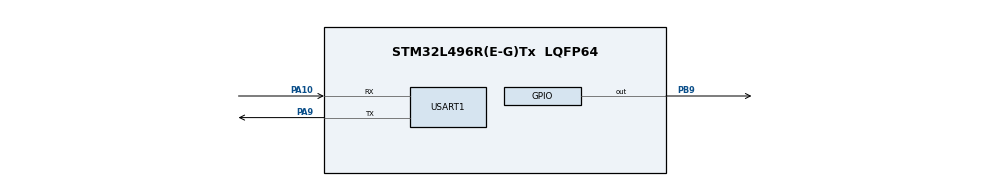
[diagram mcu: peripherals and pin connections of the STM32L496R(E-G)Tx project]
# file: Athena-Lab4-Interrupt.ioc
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FREERTOS.Tasks01=defaultTask,24,128,StartDefaultTask,Default,NULL,Dynamic,NULL,NULL
Mcu.Family=STM32L4
Mcu.Name=STM32L496R(E-G)Tx
Mcu.Package=LQFP64
NVIC.PriorityGroup=NVIC_PRIORITYGROUP_4
NVIC.TIM1_UP_TIM16_IRQn=true\:15\:0\:false\:false\:true\:false\:false\:true\:true
NVIC.TimeBase=TIM1_UP_TIM16_IRQn
NVIC.TimeBaseIP=TIM1
NVIC.USART1_IRQn=true\:5\:0\:false\:false\:true\:true\:true\:true\:true
PA10.Mode=Asynchronous
PA10.Signal=USART1_RX
PA13\ (JTMS/SWDIO).Mode=Serial_Wire
PA13\ (JTMS/SWDIO).Signal=SYS_JTMS-SWDIO
PA14\ (JTCK/SWCLK).Mode=Serial_Wire
PA14\ (JTCK/SWCLK).Signal=SYS_JTCK-SWCLK
PA9.Mode=Asynchronous
PA9.Signal=USART1_TX
PB9.Signal=GPIO_Output
PH0-OSC_IN\ (PH0).Mode=HSE-External-Oscillator
PH0-OSC_IN\ (PH0).Signal=RCC_OSC_IN
PH1-OSC_OUT\ (PH1).Mode=HSE-External-Oscillator
PH1-OSC_OUT\ (PH1).Signal=RCC_OSC_OUT
ProjectManager.HeapSize=0x200
ProjectManager.StackSize=0x400
ProjectManager.TargetToolchain=STM32CubeIDE
RCC.ADCFreq_Value=32000000
RCC.AHBFreq_Value=80000000
RCC.APB1Freq_Value=80000000
RCC.APB1TimFreq_Value=80000000
RCC.APB2Freq_Value=80000000
RCC.APB2TimFreq_Value=80000000
RCC.CortexFreq_Value=80000000
RCC.HCLKFreq_Value=80000000
RCC.HSE_VALUE=8000000
RCC.HSI48_VALUE=48000000
RCC.HSI_VALUE=16000000
RCC.LSE_VALUE=32768
RCC.MSI_VALUE=4000000
RCC.PLLN=20
RCC.PLLSourceVirtual=RCC_PLLSOURCE_HSE
RCC.SYSCLKFreq_VALUE=80000000
RCC.SYSCLKSource=RCC_SYSCLKSOURCE_PLLCLK
RCC.USBFreq_Value=32000000
RCC.VCOOutputFreq_Value=160000000
USART1.VirtualMode-Asynchronous=VM_ASYNC
VP_FREERTOS_VS_CMSIS_V2.Mode=CMSIS_V2
VP_SYS_VS_tim1.Mode=TIM1
board=custom

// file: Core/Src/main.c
/* USER CODE BEGIN Header */
/**
  ******************************************************************************
  * @file           : main.c
  * @brief          : Main program body
  ******************************************************************************
  * @attention
  *
  * Copyright (c) 2025 STMicroelectronics.
  * All rights reserved.
  *
  * This software is licensed under terms that can be found in the LICENSE file
  * in the root directory of this software component.
  * If no LICENSE file comes with this software, it is provided AS-IS.
  *
  ******************************************************************************
  */
/* USER CODE END Header */
#include "main.h"
#include "cmsis_os.h"
#include "usart.h"
#include "gpio.h"

void SystemClock_Config(void);
void MX_FREERTOS_Init(void);

int main(void)
{

  /* MCU Configuration--------------------------------------------------------*/

  /* Reset of all peripherals, Initializes the Flash interface and the Systick. */
  HAL_Init();

  /* Configure the system clock */
  SystemClock_Config();

  /* Initialize all configured peripherals */
  MX_GPIO_Init();
  MX_USART1_UART_Init();

  /* Init scheduler */
  osKernelInitialize();  /* Call init function for freertos objects (in cmsis_os2.c) */
  MX_FREERTOS_Init();

  /* Start scheduler */
  osKernelStart();

  /* We should never get here as control is now taken by the scheduler */

  /* Infinite loop */
  while (1)
  {

  }
}

void SystemClock_Config(void)
{
  LL_FLASH_SetLatency(LL_FLASH_LATENCY_4);
  while(LL_FLASH_GetLatency()!= LL_FLASH_LATENCY_4)
  {
  }
  LL_PWR_SetRegulVoltageScaling(LL_PWR_REGU_VOLTAGE_SCALE1);
  while (LL_PWR_IsActiveFlag_VOS() != 0)
  {
  }
  LL_RCC_HSE_Enable();

   /* Wait till HSE is ready */
  while(LL_RCC_HSE_IsReady() != 1)
  {

  }
  LL_RCC_PLL_ConfigDomain_SYS(LL_RCC_PLLSOURCE_HSE, LL_RCC_PLLM_DIV_1, 20, LL_RCC_PLLR_DIV_2);
  LL_RCC_PLL_EnableDomain_SYS();
  LL_RCC_PLL_Enable();

   /* Wait till PLL is ready */
  while(LL_RCC_PLL_IsReady() != 1)
  {

  }
  LL_RCC_SetSysClkSource(LL_RCC_SYS_CLKSOURCE_PLL);

   /* Wait till System clock is ready */
  while(LL_RCC_GetSysClkSource() != LL_RCC_SYS_CLKSOURCE_STATUS_PLL)
  {

  }
  LL_RCC_SetAHBPrescaler(LL_RCC_SYSCLK_DIV_1);
  LL_RCC_SetAPB1Prescaler(LL_RCC_APB1_DIV_1);
  LL_RCC_SetAPB2Prescaler(LL_RCC_APB2_DIV_1);
  LL_SetSystemCoreClock(80000000);

   /* Update the time base */
  if (HAL_InitTick (TICK_INT_PRIORITY) != HAL_OK)
  {
    Error_Handler();
  }
}

void HAL_TIM_PeriodElapsedCallback(TIM_HandleTypeDef *htim)
{
  if (htim->Instance == TIM1)
  {
    HAL_IncTick();
  }
}

void Error_Handler(void)
{
  __disable_irq();
  while (1)
  {
  }
}

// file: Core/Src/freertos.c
/* USER CODE BEGIN Header */
/**
  ******************************************************************************
  * File Name          : freertos.c
  * Description        : Code for freertos applications
  ******************************************************************************
  * @attention
  *
  * Copyright (c) 2025 STMicroelectronics.
  * All rights reserved.
  *
  * This software is licensed under terms that can be found in the LICENSE file
  * in the root directory of this software component.
  * If no LICENSE file comes with this software, it is provided AS-IS.
  *
  ******************************************************************************
  */
/* USER CODE END Header */

#include "FreeRTOS.h"
#include "task.h"
#include "main.h"
#include "cmsis_os.h"

/* USER CODE BEGIN Includes */
#include <string.h>
/* USER CODE END Includes */

/* USER CODE BEGIN Variables */
//======== Add Code in this area begin ========
// Import header file, define task handle, define semaphore, declare task function

//======== Add Code in this area end ========

uint8_t work_flag = 1;
uint32_t led_blink_timedelay = 1000;
usart1_rxbuffer rx_buffer;
/* USER CODE END Variables */
/* Definitions for defaultTask */
osThreadId_t defaultTaskHandle;
const osThreadAttr_t defaultTask_attributes = {
  .name = "defaultTask",
  .stack_size = 128 * 4,
  .priority = (osPriority_t) osPriorityNormal,
};

void StartDefaultTask(void *argument);

void MX_FREERTOS_Init(void); /* (MISRA C 2004 rule 8.1) */

void MX_FREERTOS_Init(void) {

  /* USER CODE BEGIN RTOS_SEMAPHORES */
  /* add semaphores, ... */

  //======== Add Code in this area begin ========

  xUsartRxSemaphore = xSemaphoreCreateBinary();

  //======== Add Code in this area end ========

  /* USER CODE END RTOS_SEMAPHORES */

  /* Create the thread(s) */
  /* creation of defaultTask */
  defaultTaskHandle = osThreadNew(StartDefaultTask, NULL, &defaultTask_attributes);

  /* USER CODE BEGIN RTOS_THREADS */
  /* add threads, ... */
  UsartTaskHandle = osThreadNew(UartParseTask, NULL, &UsartTaskHandle_attributes);
  /* USER CODE END RTOS_THREADS */

}

void StartDefaultTask(void *argument)
{
  /* USER CODE BEGIN StartDefaultTask */
  /* Infinite loop */
  for(;;)
  {
	if(work_flag) {
		LL_GPIO_TogglePin(GPIOB, LL_GPIO_PIN_9);
	}
	osDelay(led_blink_timedelay);
  }
  /* USER CODE END StartDefaultTask */
}

/* USER CODE BEGIN Application */
void Usart_data_parse(uint8_t *data, uint16_t len)
{
  char* data_str = (char*)data;
  if(strcmp(data_str, "STOP") == 0){
    work_flag = 0;
    return ;
  }else if (strcmp(data_str, "START") == 0) {
    work_flag = 1;
    return ;
  }
  if(data_str[0] == 'D' && data_str[1] == ':') {
    uint32_t delay_value = 0;
    for(int i = 2; i < len; i++) {
      if(data_str[i] < '0' || data_str[i] > '9') {
        continue; // Invalid character, continue
      }
      delay_value = delay_value * 10 + (data_str[i] - '0');
    }
    if(delay_value > 0){
      work_flag = 1;
      led_blink_timedelay = delay_value;
    }
  }
}

//======== Add Code in this area begin ========
void UartParseTask(void *argument)
{
  while (1) {
	 // Add Code here
	 // Obtain semaphore and parse the received content

  }
}
//======== Add Code in this area end ========
/* USER CODE END Application */
